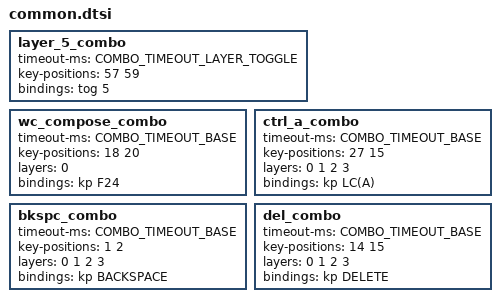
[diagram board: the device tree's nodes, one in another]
        layer_5_combo {
            timeout-ms    = <COMBO_TIMEOUT_LAYER_TOGGLE>;
            key-positions = <57  59>;         /* &mo1 + &mo2 */
            bindings      = <&tog 5>;
        };

        wc_compose_combo {
            timeout-ms    = <COMBO_TIMEOUT_BASE>;
            key-positions = <18 20>;           /* &kp t + &kp y */
            layers        = <0>;
            bindings      = <&kp F24>;
        };

        ctrl_a_combo {
            timeout-ms    = <COMBO_TIMEOUT_BASE>;
            key-positions = <27  15>;         /* &kp a + &kp w */
            layers        = <0 1 2 3>;
            bindings      = <&kp LC(A)>;
        };

        bkspc_combo {
            timeout-ms    = <COMBO_TIMEOUT_BASE>;
            key-positions = <1  2>;           /* &kp 1 + &kp 2 */
            layers        = <0 1 2 3>;
            bindings      = <&kp BACKSPACE>;
        };

        del_combo {
            timeout-ms    = <COMBO_TIMEOUT_BASE>;
            key-positions = <14  15>;         /* &kp q + &kp w */
            layers        = <0 1 2 3>;
            bindings      = <&kp DELETE>;
        };
